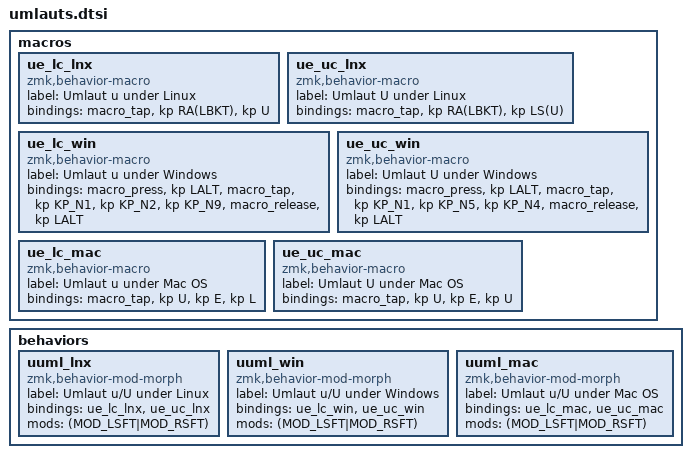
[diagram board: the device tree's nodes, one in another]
// TODO: deactivate other layers on activation of a specific layer

macros {
    ue_lc_lnx: ue_lc_lnx {
        label = "Umlaut u under Linux";
        compatible = "zmk,behavior-macro";
        #binding-cells = <0>;
        bindings
            = <&macro_tap &kp RA(LBKT) &kp U>
            ;
    };
    ue_uc_lnx: ue_uc_lnx {
        label = "Umlaut U under Linux";
        compatible = "zmk,behavior-macro";
        #binding-cells = <0>;
        bindings
            = <&macro_tap &kp RA(LBKT) &kp LS(U)>
            ;
    };
    ue_lc_win: ue_lc_win {
        label = "Umlaut u under Windows";
        compatible = "zmk,behavior-macro";
        #binding-cells = <0>;
        bindings
            = <&macro_press &kp LALT>
            , <&macro_tap &kp KP_N1 &kp KP_N2 &kp KP_N9>
            , <&macro_release &kp LALT>
            ;
    };
    ue_uc_win: ue_uc_win {
        label = "Umlaut U under Windows";
        compatible = "zmk,behavior-macro";
        #binding-cells = <0>;
        bindings
            = <&macro_press &kp LALT>
            , <&macro_tap &kp KP_N1 &kp KP_N5 &kp KP_N4>
            , <&macro_release &kp LALT>
            ;
    };
    ue_lc_mac: ue_lc_mac {
        label = "Umlaut u under Mac OS";
        compatible = "zmk,behavior-macro";
        #binding-cells = <0>;
        bindings
            = <&macro_tap &kp U &kp E &kp L>
            ;
    };
    ue_uc_mac: ue_uc_mac {
        label = "Umlaut U under Mac OS";
        compatible = "zmk,behavior-macro";
        #binding-cells = <0>;
        bindings
            = <&macro_tap &kp U &kp E &kp U>
            ;
    };
};

behaviors {
    uuml_lnx: uuml_lnx {
        compatible = "zmk,behavior-mod-morph";
        label = "Umlaut u/U under Linux";
        #binding-cells = <0>;
        bindings = <&ue_lc_lnx>, <&ue_uc_lnx>;
        mods = <(MOD_LSFT|MOD_RSFT)>;
    };
    uuml_win: uuml_win {
        compatible = "zmk,behavior-mod-morph";
        label = "Umlaut u/U under Windows";
        #binding-cells = <0>;
        bindings = <&ue_lc_win>, <&ue_uc_win>;
        mods = <(MOD_LSFT|MOD_RSFT)>;
    };
    uuml_mac: uuml_mac {
        compatible = "zmk,behavior-mod-morph";
        label = "Umlaut u/U under Mac OS";
        #binding-cells = <0>;
        bindings = <&ue_lc_mac>, <&ue_uc_mac>;
        mods = <(MOD_LSFT|MOD_RSFT)>;
    };
};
